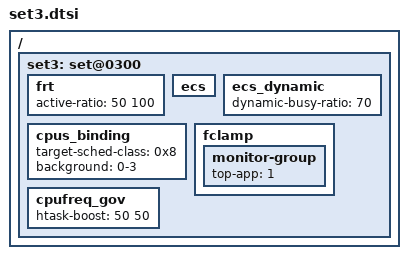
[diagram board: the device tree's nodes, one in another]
/ {
	/* game mode - default */
	set3: set@0300{
		frt {	   			/* LIT BIG */
			active-ratio 		= < 50 100>;
		};

		ecs { };

		ecs_dynamic {
			dynamic-busy-ratio		= <70>;
		};


		/* cpus_binding applied to core selection */
		cpus_binding {
			target-sched-class = <0x8>;	/* fair */

			background	= "0-3";
		};

		fclamp {
			monitor-group {
				top-app         = <1>;
			};
		};

		cpufreq_gov {
				/* LIT BIG */
			htask-boost = < 50 50 >;
		};
	};
};
